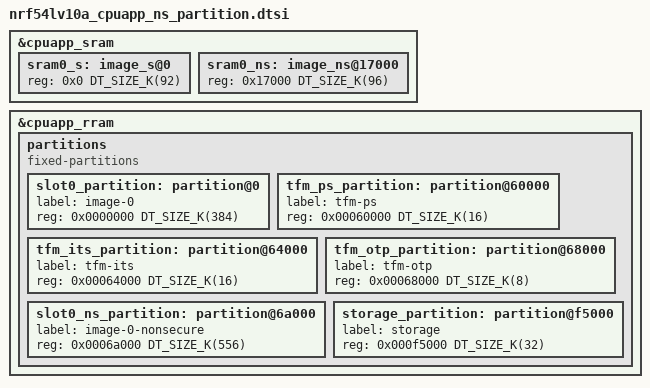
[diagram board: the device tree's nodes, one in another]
/*
 * Copyright (c) 2026 Nordic Semiconductor ASA
 *
 * SPDX-License-Identifier: LicenseRef-Nordic-5-Clause
 */

/*
 * Default SRAM planning when building for nRF54LV10A with ARM TrustZone-M support
 * - Lowest 92 kB SRAM allocated to Secure image (sram0_s).
 * - Upper 96 kB SRAM allocated to Non-Secure image (sram0_ns).
 *
 * nRF54LV10A has 192 kB of volatile memory (SRAM). 92 + 96 = 188 kB used;
 * 4 kB at the top is left unused.
 * This static layout needs to be the same with the upstream TF-M layout in the
 * header flash_layout.h of the relevant platform. Any updates in the layout
 * need to happen both in the flash_layout.h and in this file at the same time.
 */

&cpuapp_sram {
	sram0_s: image_s@0 {
		#address-cells = <1>;
		#size-cells = <1>;
		/* Secure image memory */
		reg = <0x0 DT_SIZE_K(92)>;
		ranges = <0x0 0x0 DT_SIZE_K(92)>;
	};

	sram0_ns: image_ns@17000 {
		#address-cells = <1>;
		#size-cells = <1>;
		/* Non-Secure image memory */
		reg = <0x17000 DT_SIZE_K(96)>;
		ranges = <0x0 0x17000 DT_SIZE_K(96)>;
	};
};

&cpuapp_rram {
	partitions {
		compatible = "fixed-partitions";
		#address-cells = <1>;
		#size-cells = <1>;

		/* nRF54LV10A has 1012 kB of non volatile memory (RRAM).
		 *
		 * This static layout needs to be the same with the upstream TF-M layout in the
		 * header flash_layout.h of the relevant platform. Any updates in the layout
		 * need to happen both in the flash_layout.h and in this file at the same time.
		 */
		slot0_partition: partition@0 {
			label = "image-0";
			reg = <0x0000000 DT_SIZE_K(384)>;
		};

		tfm_ps_partition: partition@60000 {
			label = "tfm-ps";
			reg = <0x00060000 DT_SIZE_K(16)>;
		};

		tfm_its_partition: partition@64000 {
			label = "tfm-its";
			reg = <0x00064000 DT_SIZE_K(16)>;
		};

		tfm_otp_partition: partition@68000 {
			label = "tfm-otp";
			reg = <0x00068000 DT_SIZE_K(8)>;
		};

		slot0_ns_partition: partition@6a000 {
			label = "image-0-nonsecure";
			reg = <0x0006a000 DT_SIZE_K(556)>;
		};

		storage_partition: partition@f5000 {
			label = "storage";
			reg = <0x000f5000 DT_SIZE_K(32)>;
		};
	};
};
